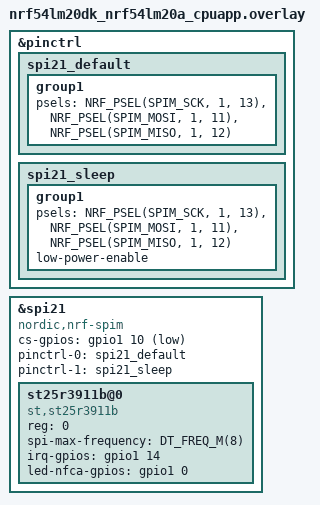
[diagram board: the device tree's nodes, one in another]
/*
 * Copyright (c) 2025 Nordic Semiconductor ASA
 *
 * SPDX-License-Identifier: LicenseRef-Nordic-5-Clause
 */

 &pinctrl {
	spi21_default: spi21_default {
		group1 {
			psels = <NRF_PSEL(SPIM_SCK, 1, 13)>,
			        <NRF_PSEL(SPIM_MOSI, 1, 11)>,
			        <NRF_PSEL(SPIM_MISO, 1, 12)>;
		};
	};

	spi21_sleep: spi21_sleep {
		group1 {
			psels = <NRF_PSEL(SPIM_SCK, 1, 13)>,
			        <NRF_PSEL(SPIM_MOSI, 1, 11)>,
			        <NRF_PSEL(SPIM_MISO, 1, 12)>;
			low-power-enable;
		};
	};
};

&spi21 {
	compatible = "nordic,nrf-spim";
	status = "okay";
	cs-gpios = <&gpio1 10 GPIO_ACTIVE_LOW>;

	pinctrl-0 = <&spi21_default>;
	pinctrl-1 = <&spi21_sleep>;
	pinctrl-names = "default", "sleep";
	st25r3911b@0 {
		compatible = "st,st25r3911b";
		reg = <0>;
		spi-max-frequency = <DT_FREQ_M(8)>;
		irq-gpios = <&gpio1 14 GPIO_ACTIVE_HIGH>;
		led-nfca-gpios = <&gpio1 0 GPIO_ACTIVE_HIGH>;
	};
};
